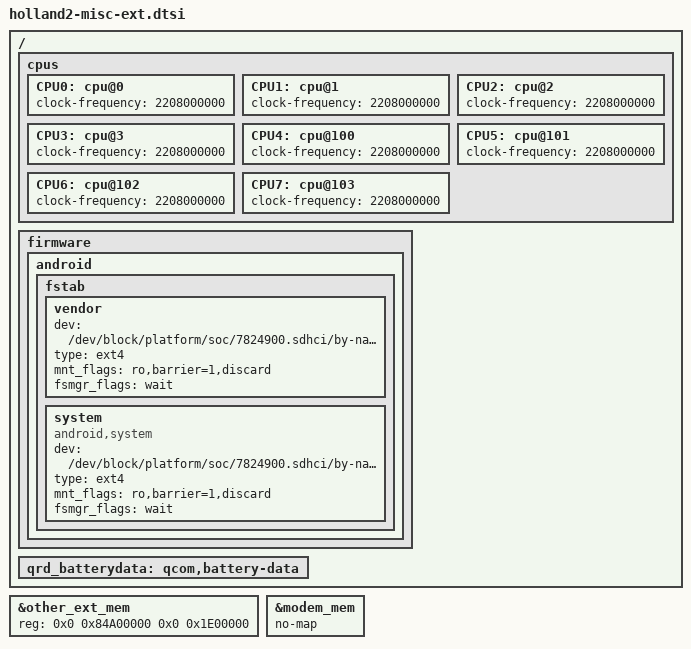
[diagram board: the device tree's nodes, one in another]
/* Copyright (c) 2020, The Linux Foundation. All rights reserved.
*  Copyright (c) 2020, Jebaitedneko.
*
* This program is free software; you can redistribute it and/or modify
* it under the terms of the GNU General Public License version 2 and
* only version 2 as published by the Free Software Foundation.
*
* This program is distributed in the hope that it will be useful,
* but WITHOUT ANY WARRANTY; without even the implied warranty of
* MERCHANTABILITY or FITNESS FOR A PARTICULAR PURPOSE.  See the
* GNU General Public License for more details.
*/

/ {

	cpus {
		CPU0: cpu@0 {
			clock-frequency = <2208000000>;
		};
		CPU1: cpu@1 {
			clock-frequency = <2208000000>;
		};
		CPU2: cpu@2 {
			clock-frequency = <2208000000>;
		};
		CPU3: cpu@3 {
			clock-frequency = <2208000000>;
		};
		CPU4: cpu@100 {
			clock-frequency = <2208000000>;
		};
		CPU5: cpu@101 {
			clock-frequency = <2208000000>;
		};
		CPU6: cpu@102 {
			clock-frequency = <2208000000>;
		};
		CPU7: cpu@103 {
			clock-frequency = <2208000000>;
		};
	};

	firmware: firmware {

		android {

			fstab {

				vendor {

					dev = "/dev/block/platform/soc/7824900.sdhci/by-name/vendor";
					type = "ext4";
					mnt_flags = "ro,barrier=1,discard";
					fsmgr_flags = "wait";
					status = "okay";
				};

				system {

					compatible = "android,system";
					dev = "/dev/block/platform/soc/7824900.sdhci/by-name/system";
					type = "ext4";
					mnt_flags = "ro,barrier=1,discard";
					fsmgr_flags = "wait";
					status = "okay";
				};
			};
		};
	};

	qrd_batterydata: qcom,battery-data {
		#include "batterydata_Amazon_4V4_4000mAh.dtsi"
	};
};

&other_ext_mem {
	reg = <0x0 0x84A00000 0x0 0x1E00000>;
};

&modem_mem {

	no-map;

	/delete-property/ no-map-fixup;

};
